AUTOSAR XML (schema 3.1.2)
package /Components/SWC_TrbActMgt
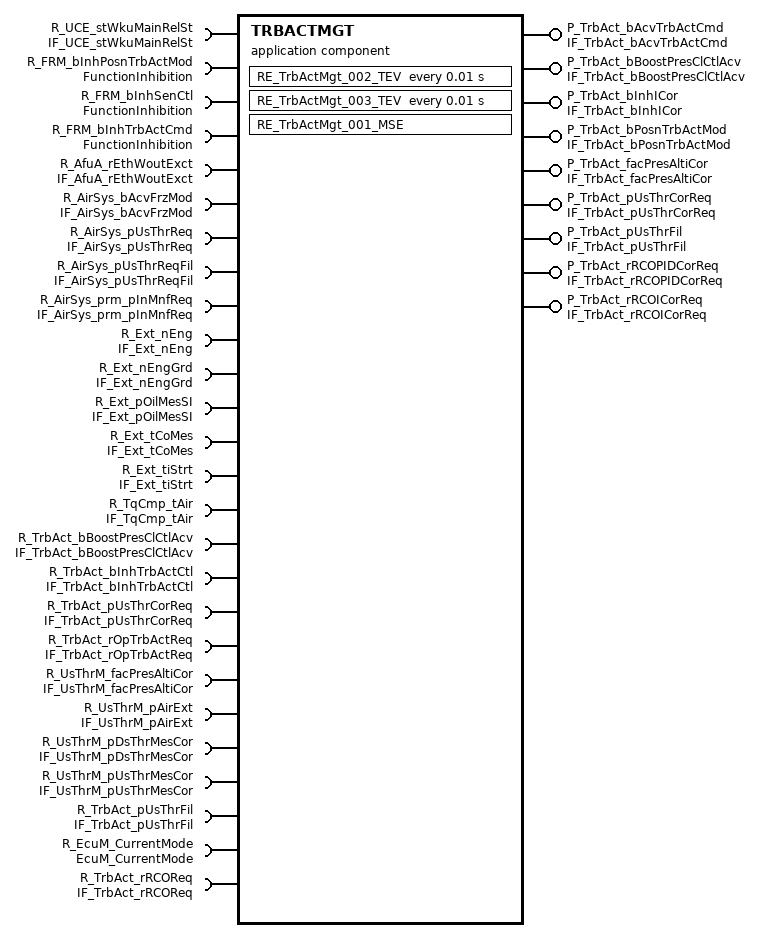
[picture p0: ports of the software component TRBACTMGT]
  application software component type TRBACTMGT  # TrbActMgt
    4 x require port:
      R_UCE_stWkuMainRelSt: required-interface=IF_UCE_stWkuMainRelSt
      R_FRM_bInhPosnTrbActMod: required-interface=FunctionInhibition
      R_FRM_bInhSenCtl: required-interface=FunctionInhibition
      R_FRM_bInhTrbActCmd: required-interface=FunctionInhibition
    9 x provide port:
      P_TrbAct_bAcvTrbActCmd: unqueued-sender-com-spec{data-element=TrbAct_bAcvTrbActCmd, can-invalidate=false, init-value=ConstantValue}, provided-interface=IF_TrbAct_bAcvTrbActCmd
      P_TrbAct_bBoostPresClCtlAcv: unqueued-sender-com-spec{data-element=TrbAct_bBoostPresClCtlAcv, can-invalidate=false, init-value=BooleanInitValue}, provided-interface=IF_TrbAct_bBoostPresClCtlAcv
      P_TrbAct_bInhICor: unqueued-sender-com-spec{data-element=TrbAct_bInhICor, can-invalidate=false, init-value=BooleanInitValue1}, provided-interface=IF_TrbAct_bInhICor
      P_TrbAct_bPosnTrbActMod: unqueued-sender-com-spec{data-element=TrbAct_bPosnTrbActMod, can-invalidate=false, init-value=BooleanInitValue3}, provided-interface=IF_TrbAct_bPosnTrbActMod
      P_TrbAct_facPresAltiCor: unqueued-sender-com-spec{data-element=TrbAct_facPresAltiCor, can-invalidate=false, init-value=UInt16InitValue}, provided-interface=IF_TrbAct_facPresAltiCor
      P_TrbAct_pUsThrCorReq: unqueued-sender-com-spec{data-element=TrbAct_pUsThrCorReq, can-invalidate=false, init-value=ConstantValue5}, provided-interface=IF_TrbAct_pUsThrCorReq
      P_TrbAct_pUsThrFil: unqueued-sender-com-spec{data-element=TrbAct_pUsThrFil, can-invalidate=false, init-value=ConstantValue7}, provided-interface=IF_TrbAct_pUsThrFil
      P_TrbAct_rRCOPIDCorReq: unqueued-sender-com-spec{data-element=TrbAct_rRCOPIDCorReq, can-invalidate=false, init-value=ConstantValue9}, provided-interface=IF_TrbAct_rRCOPIDCorReq
      P_TrbAct_rRCOICorReq: unqueued-sender-com-spec{data-element=TrbAct_rRCOICorReq, can-invalidate=false, init-value=ConstantValue11}, provided-interface=IF_TrbAct_rRCOICorReq
    22 x require port:
      R_AfuA_rEthWoutExct: unqueued-receiver-com-spec{data-element=AfuA_rEthWoutExct, init-value=UInt8InitValue, resync-time=0}, required-interface=IF_AfuA_rEthWoutExct
      R_AirSys_bAcvFrzMod: unqueued-receiver-com-spec{data-element=AirSys_bAcvFrzMod, init-value=ConstantValue13, resync-time=0}, required-interface=IF_AirSys_bAcvFrzMod
      R_AirSys_pUsThrReq: unqueued-receiver-com-spec{data-element=AirSys_pUsThrReq, init-value=ConstantValue15, resync-time=0}, required-interface=IF_AirSys_pUsThrReq
      R_AirSys_pUsThrReqFil: unqueued-receiver-com-spec{data-element=AirSys_pUsThrReqFil, init-value=ConstantValue17, resync-time=0}, required-interface=IF_AirSys_pUsThrReqFil
      R_AirSys_prm_pInMnfReq: unqueued-receiver-com-spec{data-element=AirSys_prm_pInMnfReq, init-value=ArrayConstantValue, resync-time=0}, required-interface=IF_AirSys_prm_pInMnfReq
      R_Ext_nEng: unqueued-receiver-com-spec{data-element=Ext_nEng, init-value=ConstantValue19, resync-time=0}, required-interface=IF_Ext_nEng
      R_Ext_nEngGrd: unqueued-receiver-com-spec{data-element=Ext_nEngGrd, init-value=SInt8InitValue, resync-time=0}, required-interface=IF_Ext_nEngGrd
      R_Ext_pOilMesSI: unqueued-receiver-com-spec{data-element=Ext_pOilMesSI, init-value=UInt16InitValue21, resync-time=0}, required-interface=IF_Ext_pOilMesSI
      R_Ext_tCoMes: unqueued-receiver-com-spec{data-element=Ext_tCoMes, init-value=SInt16InitValue, resync-time=0}, required-interface=IF_Ext_tCoMes
      R_Ext_tiStrt: unqueued-receiver-com-spec{data-element=Ext_tiStrt, init-value=UInt16InitValue23, resync-time=0}, required-interface=IF_Ext_tiStrt
      R_TqCmp_tAir: unqueued-receiver-com-spec{data-element=TqCmp_tAir, init-value=SInt8InitValue25, resync-time=0}, required-interface=IF_TqCmp_tAir
      R_TrbAct_bBoostPresClCtlAcv: unqueued-receiver-com-spec{data-element=TrbAct_bBoostPresClCtlAcv, init-value=BooleanInitValue, resync-time=0}, required-interface=IF_TrbAct_bBoostPresClCtlAcv
      R_TrbAct_bInhTrbActCtl: unqueued-receiver-com-spec{data-element=TrbAct_bInhTrbActCtl, init-value=ConstantValue27, resync-time=0}, required-interface=IF_TrbAct_bInhTrbActCtl
      R_TrbAct_pUsThrCorReq: unqueued-receiver-com-spec{data-element=TrbAct_pUsThrCorReq, init-value=ConstantValue29, resync-time=0}, required-interface=IF_TrbAct_pUsThrCorReq
      R_TrbAct_rOpTrbActReq: unqueued-receiver-com-spec{data-element=TrbAct_rOpTrbActReq, init-value=ConstantValue31, resync-time=0}, required-interface=IF_TrbAct_rOpTrbActReq
      R_UsThrM_facPresAltiCor: unqueued-receiver-com-spec{data-element=UsThrM_facPresAltiCor, init-value=UInt16InitValue33, resync-time=0}, required-interface=IF_UsThrM_facPresAltiCor
      R_UsThrM_pAirExt: unqueued-receiver-com-spec{data-element=UsThrM_pAirExt, init-value=ConstantValue35, resync-time=0}, required-interface=IF_UsThrM_pAirExt
      R_UsThrM_pDsThrMesCor: unqueued-receiver-com-spec{data-element=UsThrM_pDsThrMesCor, init-value=ConstantValue37, resync-time=0}, required-interface=IF_UsThrM_pDsThrMesCor
      R_UsThrM_pUsThrMesCor: unqueued-receiver-com-spec{data-element=UsThrM_pUsThrMesCor, init-value=ConstantValue39, resync-time=0}, required-interface=IF_UsThrM_pUsThrMesCor
      R_TrbAct_pUsThrFil: unqueued-receiver-com-spec{data-element=TrbAct_pUsThrFil, init-value=ConstantValue41, resync-time=0}, required-interface=IF_TrbAct_pUsThrFil
      R_EcuM_CurrentMode: required-interface=EcuM_CurrentMode
      R_TrbAct_rRCOReq: unqueued-receiver-com-spec{data-element=TrbAct_rRCOReq, init-value=ConstantValue43, resync-time=0}, required-interface=IF_TrbAct_rRCOReq
  30 x constant specification:
    ArrayConstantValue
      value:
        array specification ArrayConstantValue: type=rt_Array_UInt16_2_m2
          integer literal Const: type=DT_AirSys_prm_pInMnfReq, value=0
          integer literal Const1: type=DT_AirSys_prm_pInMnfReq, value=0
    BooleanInitValue
      value:
        boolean literal BooleanInitValue: type=DT_TrbAct_bBoostPresClCtlAcv, value=false
    BooleanInitValue1
      value:
        boolean literal BooleanInitValue1: type=DT_TrbAct_bInhICor, value=false
    BooleanInitValue3
      value:
        boolean literal BooleanInitValue3: type=DT_TrbAct_bPosnTrbActMod, value=false
    ConstantValue
      value:
        boolean literal ConstantValue: type=DT_TrbAct_bAcvTrbActCmd, value=false
    ConstantValue11
      value:
        integer literal ConstantValue11: type=DT_TrbAct_rRCOICorReq, value=0
    ConstantValue13
      value:
        boolean literal ConstantValue13: type=DT_AirSys_bAcvFrzMod, value=false
    ConstantValue15
      value:
        integer literal ConstantValue15: type=DT_AirSys_pUsThrReq, value=0
    ConstantValue17
      value:
        integer literal ConstantValue17: type=DT_AirSys_pUsThrReqFil, value=0
    ConstantValue19
      value:
        integer literal ConstantValue19: type=DT_Ext_nEng, value=0
    ConstantValue27
      value:
        boolean literal ConstantValue27: type=DT_TrbAct_bInhTrbActCtl, value=true
    ConstantValue29
      value:
        integer literal ConstantValue29: type=DT_TrbAct_pUsThrCorReq, value=0
    ConstantValue31
      value:
        integer literal ConstantValue31: type=DT_TrbAct_rOpTrbActReq, value=0
    ConstantValue35
      value:
        integer literal ConstantValue35: type=DT_UsThrM_pAirExt, value=0
    ConstantValue37
      value:
        integer literal ConstantValue37: type=DT_UsThrM_pDsThrMesCor, value=0
    ConstantValue39
      value:
        integer literal ConstantValue39: type=DT_UsThrM_pUsThrMesCor, value=0
    ConstantValue41
      value:
        integer literal ConstantValue41: type=DT_TrbAct_pUsThrFil, value=0
    ConstantValue43
      value:
        integer literal ConstantValue43: type=DT_TrbAct_rRCOReq, value=0
    ConstantValue5
      value:
        integer literal ConstantValue5: type=DT_TrbAct_pUsThrCorReq, value=0
    ConstantValue7
      value:
        integer literal ConstantValue7: type=DT_TrbAct_pUsThrFil, value=0
    ConstantValue9
      value:
        integer literal ConstantValue9: type=DT_TrbAct_rRCOPIDCorReq, value=0
    InitValue_SInt16_0
      value:
        integer literal InitValue_SInt16_0: type=DT_TrbAct_pUsThrICorReq_irv, value=0
    SInt16InitValue
      value:
        integer literal SInt16InitValue: type=DT_Ext_tCoMes, value=20
    SInt8InitValue
      value:
        integer literal SInt8InitValue: type=DT_Ext_nEngGrd, value=0
    SInt8InitValue25
      value:
        integer literal SInt8InitValue25: type=DT_TqCmp_tAir, value=-40
    UInt16InitValue
      value:
        integer literal UInt16InitValue: type=DT_TrbAct_facPresAltiCor, value=0
    UInt16InitValue21
      value:
        integer literal UInt16InitValue21: type=DT_Ext_pOilMesSI, value=0
    UInt16InitValue23
      value:
        integer literal UInt16InitValue23: type=DT_Ext_tiStrt, value=0
    UInt16InitValue33
      value:
        integer literal UInt16InitValue33: type=DT_UsThrM_facPresAltiCor, value=0
    UInt8InitValue
      value:
        integer literal UInt8InitValue: type=DT_AfuA_rEthWoutExct, value=0
  internal behavior IB_TrbActMgt: component=TRBACTMGT
    timing event EV_TrbActMgt_002_TEV: start-on-event=RE_TrbActMgt_002_TEV, period=0.01
    timing event EV_TrbActMgt_003_TEV: start-on-event=RE_TrbActMgt_003_TEV, period=0.01
    mode switch event EV_TrbActMgt_001_MSE: start-on-event=RE_TrbActMgt_001_MSE, activation=ENTRY, mode=R_EcuM_CurrentMode.currentMode.RUN
    inter runnable variable TrbAct_pUsThrICorReq_irv: sw-calibration-access=READ-WRITE, type=DT_TrbAct_pUsThrICorReq_irv, communication-approach=EXPLICIT, init-value=InitValue_SInt16_0
    runnable RE_TrbActMgt_001_MSE: written-variable=TrbAct_pUsThrICorReq_irv
      data receive point dr_UsThrM_pAirExt: data-element=R_UsThrM_pAirExt.UsThrM_pAirExt
      9 x data send point:
        ds_TrbAct_pUsThrCorReq: data-element=P_TrbAct_pUsThrCorReq.TrbAct_pUsThrCorReq
        ds_TrbAct_pUsThrFil: data-element=P_TrbAct_pUsThrFil.TrbAct_pUsThrFil
        ds_TrbAct_rRCOICorReq: data-element=P_TrbAct_rRCOICorReq.TrbAct_rRCOICorReq
        ds_TrbAct_bInhICor: data-element=P_TrbAct_bInhICor.TrbAct_bInhICor
        ds_TrbAct_facPresAltiCor: data-element=P_TrbAct_facPresAltiCor.TrbAct_facPresAltiCor
        ds_TrbAct_bBoostPresClCtlAcv: data-element=P_TrbAct_bBoostPresClCtlAcv.TrbAct_bBoostPresClCtlAcv
        ds_TrbAct_rRCOPIDCorReq: data-element=P_TrbAct_rRCOPIDCorReq.TrbAct_rRCOPIDCorReq
        ds_TrbAct_bAcvTrbActCmd: data-element=P_TrbAct_bAcvTrbActCmd.TrbAct_bAcvTrbActCmd
        ds_TrbAct_bPosnTrbActMod: data-element=P_TrbAct_bPosnTrbActMod.TrbAct_bPosnTrbActMod
    runnable RE_TrbActMgt_003_TEV: read-variable=TrbAct_pUsThrICorReq_irv, written-variable=TrbAct_pUsThrICorReq_irv
      13 x data receive point:
        dr_TrbAct_pUsThrFil: data-element=R_TrbAct_pUsThrFil.TrbAct_pUsThrFil
        dr_Ext_nEngGrd: data-element=R_Ext_nEngGrd.Ext_nEngGrd
        dr_Ext_nEng: data-element=R_Ext_nEng.Ext_nEng
        dr_AirSys_pUsThrReqFil: data-element=R_AirSys_pUsThrReqFil.AirSys_pUsThrReqFil
        dr_UsThrM_pAirExt: data-element=R_UsThrM_pAirExt.UsThrM_pAirExt
        dr_TrbAct_rOpTrbActReq: data-element=R_TrbAct_rOpTrbActReq.TrbAct_rOpTrbActReq
        dr_UsThrM_pDsThrMesCor: data-element=R_UsThrM_pDsThrMesCor.UsThrM_pDsThrMesCor
        dr_TrbAct_pUsThrCorReq: data-element=R_TrbAct_pUsThrCorReq.TrbAct_pUsThrCorReq
        dr_TrbAct_bInhTrbActCtl: data-element=R_TrbAct_bInhTrbActCtl.TrbAct_bInhTrbActCtl
        dr_AirSys_bAcvFrzMod: data-element=R_AirSys_bAcvFrzMod.AirSys_bAcvFrzMod
        dr_TrbAct_bBoostPresClCtlAcv: data-element=R_TrbAct_bBoostPresClCtlAcv.TrbAct_bBoostPresClCtlAcv
        dr_TrbAct_rRCOReq: data-element=R_TrbAct_rRCOReq.TrbAct_rRCOReq
        dr_AfuA_rEthWoutExct: data-element=R_AfuA_rEthWoutExct.AfuA_rEthWoutExct
      data send point ds_TrbAct_rRCOPIDCorReq: data-element=P_TrbAct_rRCOPIDCorReq.TrbAct_rRCOPIDCorReq
      data send point ds_TrbAct_rRCOICorReq: data-element=P_TrbAct_rRCOICorReq.TrbAct_rRCOICorReq
      data send point ds_TrbAct_bInhICor: data-element=P_TrbAct_bInhICor.TrbAct_bInhICor
    runnable RE_TrbActMgt_002_TEV
      12 x data receive point:
        dr_UsThrM_pUsThrMesCor: data-element=R_UsThrM_pUsThrMesCor.UsThrM_pUsThrMesCor
        dr_TqCmp_tAir: data-element=R_TqCmp_tAir.TqCmp_tAir
        dr_AfuA_rEthWoutExct: data-element=R_AfuA_rEthWoutExct.AfuA_rEthWoutExct
        dr_Ext_tiStrt: data-element=R_Ext_tiStrt.Ext_tiStrt
        dr_AirSys_prm_pInMnfReq: data-element=R_AirSys_prm_pInMnfReq.AirSys_prm_pInMnfReq
        dr_Ext_tCoMes: data-element=R_Ext_tCoMes.Ext_tCoMes
        dr_Ext_pOilMesSI: data-element=R_Ext_pOilMesSI.Ext_pOilMesSI
        dr_AirSys_bAcvFrzMod: data-element=R_AirSys_bAcvFrzMod.AirSys_bAcvFrzMod
        dr_Ext_nEng: data-element=R_Ext_nEng.Ext_nEng
        dr_UsThrM_facPresAltiCor: data-element=R_UsThrM_facPresAltiCor.UsThrM_facPresAltiCor
        dr_TrbAct_bInhTrbActCtl: data-element=R_TrbAct_bInhTrbActCtl.TrbAct_bInhTrbActCtl
        dr_AirSys_pUsThrReq: data-element=R_AirSys_pUsThrReq.AirSys_pUsThrReq
      5 x data send point:
        ds_TrbAct_bAcvTrbActCmd: data-element=P_TrbAct_bAcvTrbActCmd.TrbAct_bAcvTrbActCmd
        ds_TrbAct_bPosnTrbActMod: data-element=P_TrbAct_bPosnTrbActMod.TrbAct_bPosnTrbActMod
        ds_TrbAct_pUsThrFil: data-element=P_TrbAct_pUsThrFil.TrbAct_pUsThrFil
        ds_TrbAct_bBoostPresClCtlAcv: data-element=P_TrbAct_bBoostPresClCtlAcv.TrbAct_bBoostPresClCtlAcv
        ds_TrbAct_facPresAltiCor: data-element=P_TrbAct_facPresAltiCor.TrbAct_facPresAltiCor
      sync call ssp_FRM_bInhSenCtl: operation=R_FRM_bInhSenCtl.GetFunctionPermission
      sync call ssp_FRM_bInhPosnTrbActMod: operation=R_FRM_bInhPosnTrbActMod.GetFunctionPermission
      sync call ssp_FRM_bInhTrbActCmd: operation=R_FRM_bInhTrbActCmd.GetFunctionPermission
  swc implementation Imp_TrbActMgt: code-generator=Real-Time Workshop Embedded Coder 5.5 (R2010a) 25-Jan-2010, programming-language=C, behavior=IB_TrbActMgt
    code-descriptors:
      code CodeDescriptor: type=SRC
        10 x xfile:
          TrbActMgt_Version_c: url=TrbActMgt_Version.c
          TrbActMgt_import_h: url=TrbActMgt_import.h
          TrbActMgt_Def_c: url=TrbActMgt_Def.c
          TrbActMgt_data_c: url=TrbActMgt_data.c
          TrbActMgt_types_h: url=TrbActMgt_types.h
          TrbActMgt_h: url=TrbActMgt.h
          TrbActMgt_MemMap_h: url=TrbActMgt_MemMap.h
          TrbActMgt_Version_h: url=TrbActMgt_Version.h
          TrbActMgt_private_h: url=TrbActMgt_private.h
          TrbActMgt_c: url=TrbActMgt.c
package /Components/SWC_TrbActMgt/TrbActMgt_IRVDatatypes
  integer type DT_TrbAct_pUsThrICorReq_irv: base-type=int16, lower-limit=-32768, upper-limit=32767
